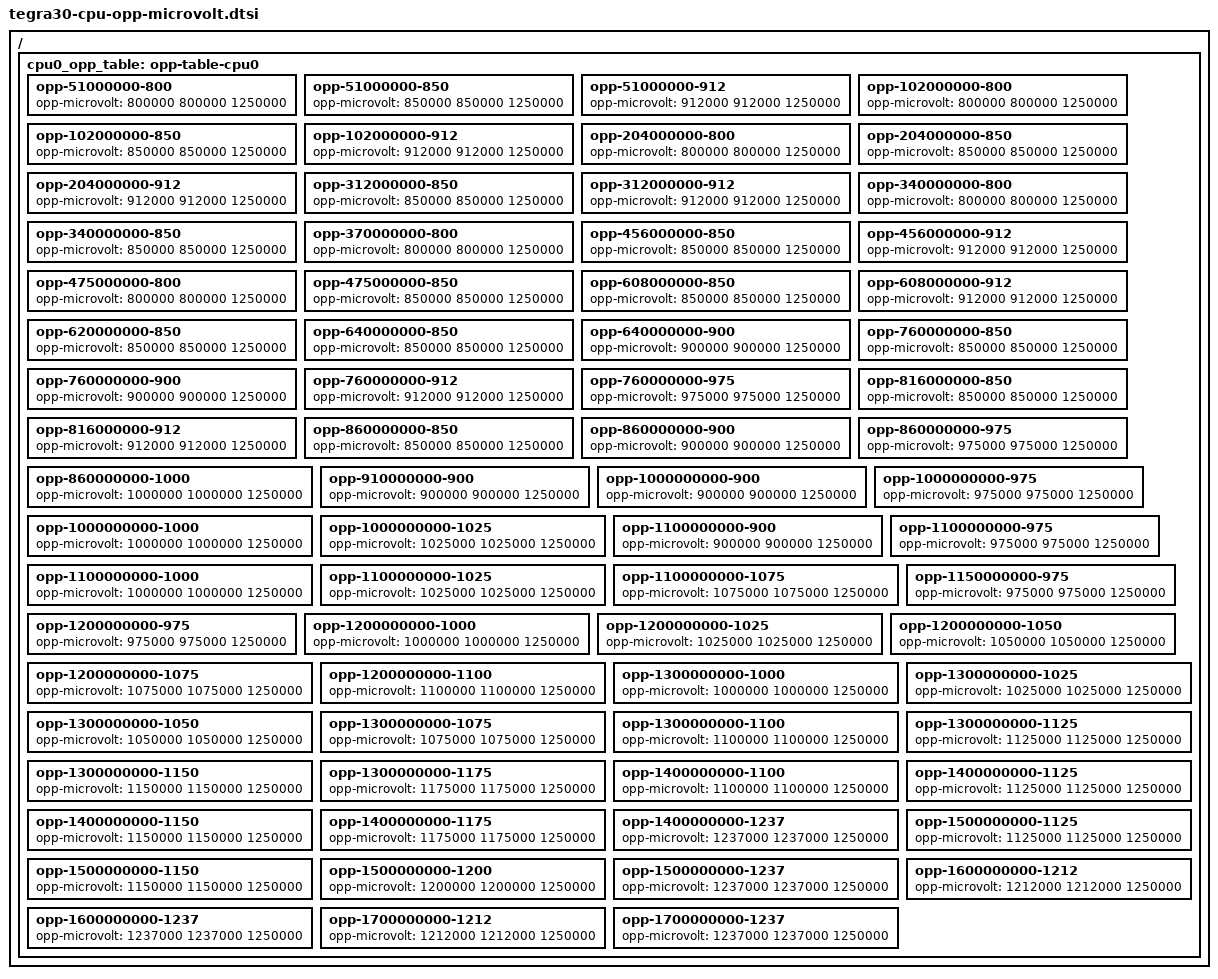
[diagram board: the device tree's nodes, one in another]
// SPDX-License-Identifier: GPL-2.0

/ {
	cpu0_opp_table: opp-table-cpu0 {
		opp-51000000-800 {
			opp-microvolt = <800000 800000 1250000>;
		};

		opp-51000000-850 {
			opp-microvolt = <850000 850000 1250000>;
		};

		opp-51000000-912 {
			opp-microvolt = <912000 912000 1250000>;
		};

		opp-102000000-800 {
			opp-microvolt = <800000 800000 1250000>;
		};

		opp-102000000-850 {
			opp-microvolt = <850000 850000 1250000>;
		};

		opp-102000000-912 {
			opp-microvolt = <912000 912000 1250000>;
		};

		opp-204000000-800 {
			opp-microvolt = <800000 800000 1250000>;
		};

		opp-204000000-850 {
			opp-microvolt = <850000 850000 1250000>;
		};

		opp-204000000-912 {
			opp-microvolt = <912000 912000 1250000>;
		};

		opp-312000000-850 {
			opp-microvolt = <850000 850000 1250000>;
		};

		opp-312000000-912 {
			opp-microvolt = <912000 912000 1250000>;
		};

		opp-340000000-800 {
			opp-microvolt = <800000 800000 1250000>;
		};

		opp-340000000-850 {
			opp-microvolt = <850000 850000 1250000>;
		};

		opp-370000000-800 {
			opp-microvolt = <800000 800000 1250000>;
		};

		opp-456000000-850 {
			opp-microvolt = <850000 850000 1250000>;
		};

		opp-456000000-912 {
			opp-microvolt = <912000 912000 1250000>;
		};

		opp-475000000-800 {
			opp-microvolt = <800000 800000 1250000>;
		};

		opp-475000000-850 {
			opp-microvolt = <850000 850000 1250000>;
		};

		opp-608000000-850 {
			opp-microvolt = <850000 850000 1250000>;
		};

		opp-608000000-912 {
			opp-microvolt = <912000 912000 1250000>;
		};

		opp-620000000-850 {
			opp-microvolt = <850000 850000 1250000>;
		};

		opp-640000000-850 {
			opp-microvolt = <850000 850000 1250000>;
		};

		opp-640000000-900 {
			opp-microvolt = <900000 900000 1250000>;
		};

		opp-760000000-850 {
			opp-microvolt = <850000 850000 1250000>;
		};

		opp-760000000-900 {
			opp-microvolt = <900000 900000 1250000>;
		};

		opp-760000000-912 {
			opp-microvolt = <912000 912000 1250000>;
		};

		opp-760000000-975 {
			opp-microvolt = <975000 975000 1250000>;
		};

		opp-816000000-850 {
			opp-microvolt = <850000 850000 1250000>;
		};

		opp-816000000-912 {
			opp-microvolt = <912000 912000 1250000>;
		};

		opp-860000000-850 {
			opp-microvolt = <850000 850000 1250000>;
		};

		opp-860000000-900 {
			opp-microvolt = <900000 900000 1250000>;
		};

		opp-860000000-975 {
			opp-microvolt = <975000 975000 1250000>;
		};

		opp-860000000-1000 {
			opp-microvolt = <1000000 1000000 1250000>;
		};

		opp-910000000-900 {
			opp-microvolt = <900000 900000 1250000>;
		};

		opp-1000000000-900 {
			opp-microvolt = <900000 900000 1250000>;
		};

		opp-1000000000-975 {
			opp-microvolt = <975000 975000 1250000>;
		};

		opp-1000000000-1000 {
			opp-microvolt = <1000000 1000000 1250000>;
		};

		opp-1000000000-1025 {
			opp-microvolt = <1025000 1025000 1250000>;
		};

		opp-1100000000-900 {
			opp-microvolt = <900000 900000 1250000>;
		};

		opp-1100000000-975 {
			opp-microvolt = <975000 975000 1250000>;
		};

		opp-1100000000-1000 {
			opp-microvolt = <1000000 1000000 1250000>;
		};

		opp-1100000000-1025 {
			opp-microvolt = <1025000 1025000 1250000>;
		};

		opp-1100000000-1075 {
			opp-microvolt = <1075000 1075000 1250000>;
		};

		opp-1150000000-975 {
			opp-microvolt = <975000 975000 1250000>;
		};

		opp-1200000000-975 {
			opp-microvolt = <975000 975000 1250000>;
		};

		opp-1200000000-1000 {
			opp-microvolt = <1000000 1000000 1250000>;
		};

		opp-1200000000-1025 {
			opp-microvolt = <1025000 1025000 1250000>;
		};

		opp-1200000000-1050 {
			opp-microvolt = <1050000 1050000 1250000>;
		};

		opp-1200000000-1075 {
			opp-microvolt = <1075000 1075000 1250000>;
		};

		opp-1200000000-1100 {
			opp-microvolt = <1100000 1100000 1250000>;
		};

		opp-1300000000-1000 {
			opp-microvolt = <1000000 1000000 1250000>;
		};

		opp-1300000000-1025 {
			opp-microvolt = <1025000 1025000 1250000>;
		};

		opp-1300000000-1050 {
			opp-microvolt = <1050000 1050000 1250000>;
		};

		opp-1300000000-1075 {
			opp-microvolt = <1075000 1075000 1250000>;
		};

		opp-1300000000-1100 {
			opp-microvolt = <1100000 1100000 1250000>;
		};

		opp-1300000000-1125 {
			opp-microvolt = <1125000 1125000 1250000>;
		};

		opp-1300000000-1150 {
			opp-microvolt = <1150000 1150000 1250000>;
		};

		opp-1300000000-1175 {
			opp-microvolt = <1175000 1175000 1250000>;
		};

		opp-1400000000-1100 {
			opp-microvolt = <1100000 1100000 1250000>;
		};

		opp-1400000000-1125 {
			opp-microvolt = <1125000 1125000 1250000>;
		};

		opp-1400000000-1150 {
			opp-microvolt = <1150000 1150000 1250000>;
		};

		opp-1400000000-1175 {
			opp-microvolt = <1175000 1175000 1250000>;
		};

		opp-1400000000-1237 {
			opp-microvolt = <1237000 1237000 1250000>;
		};

		opp-1500000000-1125 {
			opp-microvolt = <1125000 1125000 1250000>;
		};

		opp-1500000000-1150 {
			opp-microvolt = <1150000 1150000 1250000>;
		};

		opp-1500000000-1200 {
			opp-microvolt = <1200000 1200000 1250000>;
		};

		opp-1500000000-1237 {
			opp-microvolt = <1237000 1237000 1250000>;
		};

		opp-1600000000-1212 {
			opp-microvolt = <1212000 1212000 1250000>;
		};

		opp-1600000000-1237 {
			opp-microvolt = <1237000 1237000 1250000>;
		};

		opp-1700000000-1212 {
			opp-microvolt = <1212000 1212000 1250000>;
		};

		opp-1700000000-1237 {
			opp-microvolt = <1237000 1237000 1250000>;
		};
	};
};
